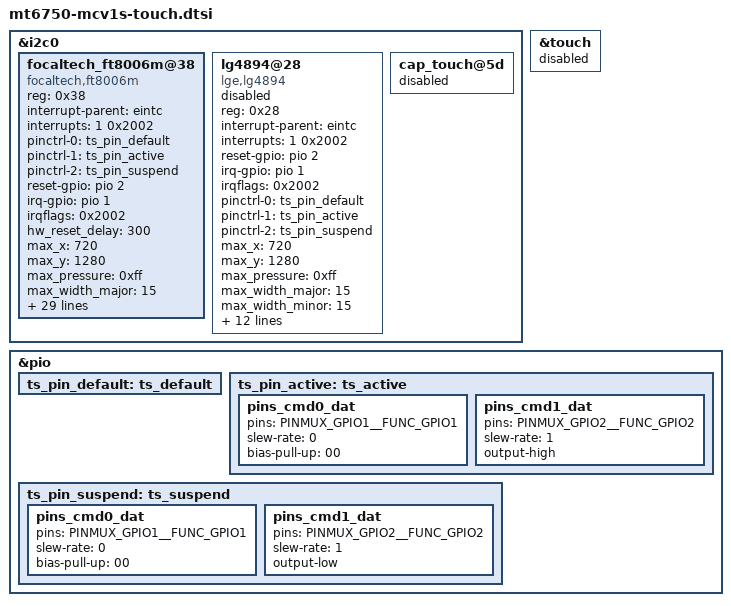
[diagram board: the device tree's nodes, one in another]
/*
 * LG Electronics LS7 touch device tree source
 *
 * Copyright (c) 2017 LG Electronics Co., Ltd.
 *              http://www.lge.com
 *
 */

&i2c0 {

	focaltech_ft8006m@38 {
		compatible = "focaltech,ft8006m";
		status = "ok";

		reg = <0x38>;
		interrupt-parent = <&eintc>;
		interrupts = <1 0x2002>;

		/* IRQF_ONESHOT		0x00002000 */
		/* IRQF_TRIGGER_FALLING		0x00000002 */
		/* IRQF_NO_SUSPEND		0x00004000 */

		pinctrl-names = "default", "touch_pin_active", "touch_pin_sleep";	/* Touch GPIO pin name setting */
		pinctrl-0 = <&ts_pin_default>;
		pinctrl-1 = <&ts_pin_active>;		/* Touch GPIO pin active setting */
		pinctrl-2 = <&ts_pin_suspend>;		/* Touch GPIO pin suspend setting */

		reset-gpio = <&pio 2 0x00>;
		irq-gpio = <&pio 1 0x2002>;
		//vdd-gpio = <&tlmm 3 0x0>;		/* ???? 3 : ph2 3.3v/l5 mipi 1.2v */
		//vio-gpio = <&tlmm 63 0x0>;		/* ???? 63 : 1.8v io*/

		irqflags = <0x2002>;
		hw_reset_delay = <300>;

		/*Caps*/
		max_x = <720>;
		max_y = <1280>;
		max_pressure = <0xff>;
		max_width_major = <15>;
		max_width_minor = <15>;
		max_orientation = <1>;
		max_id = <10>;

		/* Role */
		use_lpwg = <1>;
		use_lpwg_test = <1>;
		hide_coordinate = <1>;

		/* firmware & panel_spec path */
		use_fw_upgrade = <1>;

		fw_image = "touch/cv1/focaltech/FT8006_Pramboot_V0.3_20160922.img",
				    "touch/cv1/focaltech/LGECV1_TM_FT8006M_VID0x8d_PID0x01_5P0_V0x8A_L0x06_20171102_all.bin",
				    "touch/cv1/focaltech/LGECV1_TCL_FT8006M_VID0x3b_PID0x01_5P0_V0x8B_L0x05_20171120_all.bin";

		/* ft8006m specific */
		//vdd-supply = <&pm8916_l17>;
		//vcc_i2c-supply = <&pm8916_l6>;
		focaltech,name = "fts";
		focaltech,family-id = <0x54>;
		//focaltech,reset-gpio = <&msmgpio 16 0x00>;
		//focaltech,irq-gpio =<&msm_gpio 13 0x00>;
		//focaltech,id1-gpio = <&msm_gpio 109 0x00>;
		//focaltech,id2-gpio = <&msm_gpio 114 0x00>;
		//focaltech,id3-gpio = <&msm_gpio 121 0x00>;
		focaltech,display-coords = <0 0 480 854>;
		focaltech,panel-coords = <0 0 1080 2000>;
		focaltech,button-map= <70 150 907>;
		focaltech,no-force-update;
		focaltech,i2c-pull-up;
		focaltech,group-id = <1>;
		focaltech,hard-reset-delay-ms = <20>;
		focaltech,soft-reset-delay-ms = <150>;
		focaltech,num-max-touches = <10>;
		focaltech,fw-name = "FT_Upgrade_App.i";
		focaltech,fw-delay-aa-ms = <50>;
		focaltech,fw-delay-55-ms = <30>;
		focaltech,fw-upgrade-id1 = <0x79>;
		focaltech,fw-upgrade-id2 = <0x03>;
		focaltech,fw-delay-readid-ms = <10>;
		focaltech,fw-delay-era-flsh-ms = <2000>;

	};

	lg4894@28 {
		compatible = "lge,lg4894";
		status = "disable";

		reg = <0x28>;

		/* GPIOs */
		interrupt-parent = <&eintc>;
		interrupts = <1 0x2002>;

		/* IRQF_ONESHOT		0x00002000 */
		/* IRQF_TRIGGER_FALLING		0x00000002 */
		/* IRQF_NO_SUSPEND		0x00004000 */

		reset-gpio = <&pio 2 0x0>;
		irq-gpio = <&pio 1 0x2002>;
		irqflags = <0x2002>;

		pinctrl-names = "default", "touch_pin_active", "touch_pin_sleep";	/* Touch GPIO pin name setting */
		pinctrl-0 = <&ts_pin_default>;
		pinctrl-1 = <&ts_pin_active>;		/* Touch GPIO pin active setting */
		pinctrl-2 = <&ts_pin_suspend>;		/* Touch GPIO pin suspend setting */

		//vdd-gpio = <&eintc 3 0x0>;  /* ???? 3 : ph2 3.3v/l5 mipi 1.2v */
		//vio-gpio = <&eintc 63 0x0>; /* ???? 63 : 1.8v io*/

		/* Caps */
		max_x = <720>;
		max_y = <1280>;
		max_pressure = <0xff>;
		max_width_major = <15>;
		max_width_minor = <15>;
		max_orientation = <1>;
		max_id = <10>;

		/* role */
		hw_reset_delay = <210>;
		sw_reset_delay = <90>;
		use_lpwg = <1>;
		use_lpwg_test = <1>;
		hide_coordinate = <1>;

		/* firmware */
		use_fw_upgrade = <1>;

		fw_image = "touch/cv1/siw/L0W50CV1_1_02.img";
		panel_spec = "touch/cv1/siw/cv1_limit.txt";
		panel_spec_mfts_folder = "touch/cv1/siw/cv1_limit_mfts.txt";
	};

	cap_touch@5d {
		status = "disabled";
	};
};

&touch {
	status = "disabled";
};

/* touch gpio start */
&pio {
	ts_pin_default: ts_default {
	};
	ts_pin_active: ts_active {
		pins_cmd0_dat {
			pins = <PINMUX_GPIO1__FUNC_GPIO1>;
			slew-rate = <0>;
			bias-pull-up = <00>;
		};
		pins_cmd1_dat {
			pins = <PINMUX_GPIO2__FUNC_GPIO2>;
			slew-rate = <1>;
			output-high;
		};
	};
	ts_pin_suspend: ts_suspend {
		pins_cmd0_dat {
			pins = <PINMUX_GPIO1__FUNC_GPIO1>;
			slew-rate = <0>;
			bias-pull-up = <00>;
		};
		pins_cmd1_dat {
			pins = <PINMUX_GPIO2__FUNC_GPIO2>;
			slew-rate = <1>;
			output-low;
		};

	};
};
/* touch gpio end */
